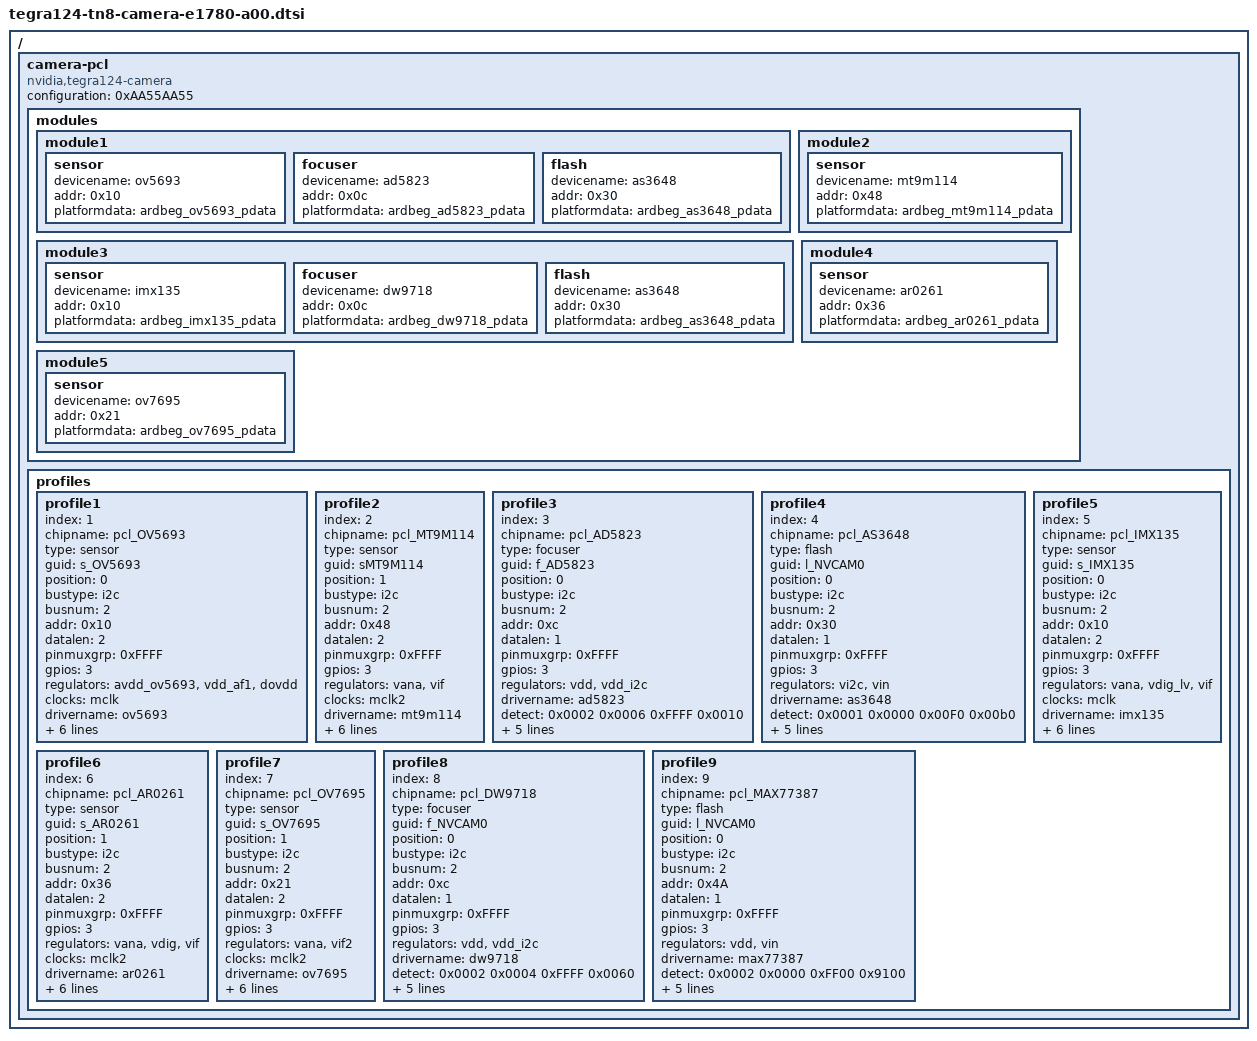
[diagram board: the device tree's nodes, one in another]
/ {
	camera-pcl {
		compatible = "nvidia,tegra124-camera", "simple-bus";
		configuration = <0xAA55AA55>;

		modules {
			module1 {
				sensor {
					devicename = "ov5693";
					addr = <0x10>;
					platformdata = "ardbeg_ov5693_pdata";
				};
				focuser {
					devicename = "ad5823";
					addr = <0x0c>;
					platformdata = "ardbeg_ad5823_pdata";
				};
				flash {
					devicename = "as3648";
					addr = <0x30>;
					platformdata = "ardbeg_as3648_pdata";
				};
			};
			module2 {
				sensor {
					devicename = "mt9m114";
					addr = <0x48>;
					platformdata = "ardbeg_mt9m114_pdata";
				};
			};
			module3 {
				sensor {
					devicename = "imx135";
					addr = <0x10>;
					platformdata = "ardbeg_imx135_pdata";
				};
				focuser {
					devicename = "dw9718";
					addr = <0x0c>;
					platformdata = "ardbeg_dw9718_pdata";
				};
				flash {
					devicename = "as3648";
					addr = <0x30>;
					platformdata = "ardbeg_as3648_pdata";
				};
			};
			module4 {
				sensor {
					devicename = "ar0261";
					addr = <0x36>;
					platformdata = "ardbeg_ar0261_pdata";
				};
			};
			module5 {
				sensor {
					devicename = "ov7695";
					addr = <0x21>;
					platformdata = "ardbeg_ov7695_pdata";
				};
			};
		};

		profiles {
			profile1 {
				index = <1>;
				chipname = "pcl_OV5693";
				type = "sensor";
				guid = "s_OV5693";
				position = <0>;
				bustype = "i2c";
				busnum = <2>;
				addr = <0x10>;
				datalen = <2>;
				pinmuxgrp = <0xFFFF>;
				gpios = <3>;
				regulators = "avdd_ov5693", "vdd_af1", "dovdd";
				clocks = "mclk";
				drivername = "ov5693";
				detect = <0x0002 0x300A 0xFFFF 0x5690>;
				devid = <0x5693>;
				poweron = <0xF0000032 10000
					0xF000001F 221
					0xF0000002 1
					0xF0000014 0x80000000
					0xF0000014 0x80000001
					0xF0000014 0x80000002
					0xF0000002 1
					0xF000001E 221
					0xF0000002 10
					0xF0000009 00000>;
				poweroff = <0xF0000032 0
					0xF000001F 221
					0xF0000001 10
					0xF0000014 2
					0xF0000014 1
					0xF0000014 0
					0xF0000009 00000>;
			};
			profile2 {
				index = <2>;
				chipname = "pcl_MT9M114";
				type = "sensor";
				guid = "sMT9M114";
				position = <1>;
				bustype = "i2c";
				busnum = <2>;
				addr = <0x48>;
				datalen = <2>;
				pinmuxgrp = <0xFFFF>;
				gpios = <3>;
				regulators = "vana", "vif";
				clocks = "mclk2";
				drivername = "mt9m114";
				detect = <0x0002 0x0000 0xFFFF 0x2481>;
				devid = <0x1040>;
				poweron = <0xF0000032 10000
					0xF000001F 219
					0xF000001E 222
					0xF0000014 0x80000000
					0xF0000014 0x80000001
					0xF0000002 10
					0xF000001F 222
					0xF000001E 219
					0xF0000002 20
					0xF0000009 00000>;
				poweroff = <0xF0000032 0
					0xF000001E 222
					0xF000001F 219
					0xF0000001 10
					0xF0000014 1
					0xF0000014 0
					0xF0000009 00000>;
			};
			profile3 {
				index = <3>;
				chipname = "pcl_AD5823";
				type = "focuser";
				guid = "f_AD5823";
				position = <0>;
				bustype = "i2c";
				busnum = <2>;
				addr = <0xc>;
				datalen = <1>;
				pinmuxgrp = <0xFFFF>;
				gpios = <3>;
				regulators = "vdd", "vdd_i2c";
				drivername = "ad5823";
				detect = <0x0002 0x0006 0xFFFF 0x0010>;
				devid = <0x5823>;
				poweron = <0xF0000014 0x80000001
					0xF0000014 0x80000000
					0xF0000001 10
					0xF000001E 223
					0xF0000001 10
					0xF0000009 00000>;
				poweroff = <0xF0000014 0
					0xF0000014 1
					0xF000001F 223
					0xF0000001 10
					0xF0000009 00000>;
			};
			profile4 {
				index = <4>;
				chipname = "pcl_AS3648";
				type = "flash";
				guid = "l_NVCAM0";
				position = <0>;
				bustype = "i2c";
				busnum = <2>;
				addr = <0x30>;
				datalen = <1>;
				pinmuxgrp = <0xFFFF>;
				gpios = <3>;
				regulators = "vi2c", "vin";
				drivername = "as3648";
				detect = <0x0001 0x0000 0x00F0 0x00b0>;
				devid = <0x3648>;
				poweron = <0xF0000014 0x80000001
					0xF0000014 0x80000000
					0xF0000001 1000
					0xF0000009 00000>;
				poweroff = <0xF0000014 0
					0xF0000014 1
					0xF0000001 10
					0xF0000009 00000>;
			};
			profile5 {
				index = <5>;
				chipname = "pcl_IMX135";
				type = "sensor";
				guid = "s_IMX135";
				position = <0>;
				bustype = "i2c";
				busnum = <2>;
				addr = <0x10>;
				datalen = <2>;
				pinmuxgrp = <0xFFFF>;
				gpios = <3>;
				regulators = "vana", "vdig_lv", "vif";
				clocks = "mclk";
				drivername = "imx135";
				detect = <0x0002 0x0016 0xFFFF 0x0135>;
				devid = <0x0135>;
				poweron = <0xF0000032 10000
					0xF000001F 221
					0xF0000001 10
					0xF0000014 0x80000002
					0xF0000014 0x80000001
					0xF0000014 0x80000000
					0xF0000002 5
					0xF000001E 221
					0xF0000001 300
					0xF0000009 00000>;
				poweroff = <0xF0000032 0
					0xF000001F 221
					0xF0000001 10
					0xF0000014 2
					0xF0000014 1
					0xF0000014 0
					0xF0000009 00000>;
			};
			profile6 {
				index = <6>;
				chipname = "pcl_AR0261";
				type = "sensor";
				guid = "s_AR0261";
				position = <1>;
				bustype = "i2c";
				busnum = <2>;
				addr = <0x36>;
				datalen = <2>;
				pinmuxgrp = <0xFFFF>;
				gpios = <3>;
				regulators = "vana", "vdig", "vif";
				clocks = "mclk2";
				drivername = "ar0261";
				detect = <0x0002 0x0003 0xFFFF 0x060A>;
				devid = <0x0261>;
				poweron = <0xF0000032 10000
					0xF000001F 219
					0xF0000014 0x80000000
					0xF0000014 0x80000001
					0xF0000014 0x80000002
					0xF0000002 40
					0xF000001E 219
					0xF0000002 20
					0xF0000009 00000>;
				poweroff = <0xF0000032 0
					0xF000001F 219
					0xF0000001 10
					0xF0000014 2
					0xF0000014 1
					0xF0000014 0
					0xF0000009 00000>;
			};
			profile7 {
				index = <7>;
				chipname = "pcl_OV7695";
				type = "sensor";
				guid = "s_OV7695";
				position = <1>;
				bustype = "i2c";
				busnum = <2>;
				addr = <0x21>;
				datalen = <2>;
				pinmuxgrp = <0xFFFF>;
				gpios = <3>;
				regulators = "vana", "vif2";
				clocks = "mclk2";
				drivername = "ov7695";
				detect = <0x0002 0x300A 0xFFFF 0x7695>;
				devid = <0x7695>;
				poweron = <0xF0000032 10000
					0xF000001F 222
					0xF0000014 0x80000000
					0xF0000014 0x80000001
					0xF0000002 40
					0xF000001E 222
					0xF0000002 10
					0xF0000009 00000>;
				poweroff = <0xF0000032 0
					0xF000001F 222
					0xF0000001 10
					0xF0000014 1
					0xF0000014 0
					0xF0000009 00000>;
			};
			profile8 {
				index = <8>;
				chipname = "pcl_DW9718";
				type = "focuser";
				guid = "f_NVCAM0";
				position = <0>;
				bustype = "i2c";
				busnum = <2>;
				addr = <0xc>;
				datalen = <1>;
				pinmuxgrp = <0xFFFF>;
				gpios = <3>;
				regulators = "vdd", "vdd_i2c";
				drivername = "dw9718";
				detect = <0x0002 0x0004 0xFFFF 0x0060>;
				devid = <0x9718>;
				poweron = <0xF0000014 0x80000001
					0xF0000014 0x80000000
					0xF0000001 10
					0xF000001E 223
					0xF0000001 10
					0xF0000009 00000>;
				poweroff = <0xF0000014 0
					0xF0000014 1
					0xF000001F 223
					0xF0000001 10
					0xF0000009 00000>;
			};
			profile9 {
				index = <9>;
				chipname = "pcl_MAX77387";
				type = "flash";
				guid = "l_NVCAM0";
				position = <0>;
				bustype = "i2c";
				busnum = <2>;
				addr = <0x4A>;
				datalen = <1>;
				pinmuxgrp = <0xFFFF>;
				gpios = <3>;
				regulators = "vdd", "vin";
				drivername = "max77387";
				detect = <0x0002 0x0000 0xFF00 0x9100>;
				devid = <0x77387>;
				poweron = <0xF0000014 0x80000001
					0xF0000014 0x80000000
					0xF0000001 10
					0xF0000009 00000>;
				poweroff = <0xF0000014 0
					0xF0000014 1
					0xF0000001 10
					0xF0000009 00000>;
			};
		};
	};
};

